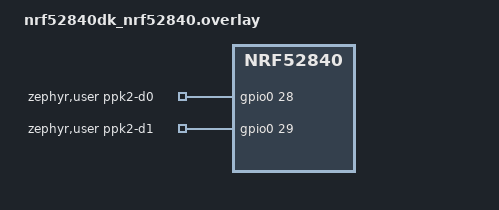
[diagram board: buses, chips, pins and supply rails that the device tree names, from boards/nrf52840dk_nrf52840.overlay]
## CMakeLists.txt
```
cmake_minimum_required(VERSION 3.20.0)
find_package(Zephyr REQUIRED HINTS $ENV{ZEPHYR_BASE})
project(zephyr_trace_demo LANGUAGES C CXX)

target_sources(app PRIVATE src/main.cpp)
target_include_directories(app PRIVATE include)
```

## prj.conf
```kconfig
# PPK2 trace-marker demo — minimal Zephyr config.
#
# GPIO for the two trace markers + the LED; C++17 for the RAII scope
# guard. Console/serial/logging are off so nothing but the workload
# shapes the current trace.

CONFIG_GPIO=y
CONFIG_CPP=y
CONFIG_STD_CPP17=y

CONFIG_LOG=n
CONFIG_PRINTK=n
CONFIG_BOOT_BANNER=n
CONFIG_CONSOLE=n
CONFIG_SERIAL=n
CONFIG_UART_CONSOLE=n
```

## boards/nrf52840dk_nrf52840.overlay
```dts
/*
 * nRF52840 DK (PCA10056) PPK2 trace pins: P0.28 (A2) -> D0,
 * P0.29 (A3) -> D1. Same pair as firmware/bench-dut (Arduino R3
 * analog header; unclaimed by default-enabled peripherals).
 */
/ {
	zephyr,user {
		ppk2-d0-gpios = <&gpio0 28 GPIO_ACTIVE_HIGH>;
		ppk2-d1-gpios = <&gpio0 29 GPIO_ACTIVE_HIGH>;
	};
};
```

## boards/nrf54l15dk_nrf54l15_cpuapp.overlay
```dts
/*
 * nRF54L15DK (PCA10156) PPK2 trace pins: P1.11 -> D0, P1.12 -> D1.
 * Same pair as firmware/bench-dut (routed to the GPIO connectors;
 * unclaimed by any default-enabled peripheral).
 */
/ {
	zephyr,user {
		ppk2-d0-gpios = <&gpio1 11 GPIO_ACTIVE_HIGH>;
		ppk2-d1-gpios = <&gpio1 12 GPIO_ACTIVE_HIGH>;
	};
};
```

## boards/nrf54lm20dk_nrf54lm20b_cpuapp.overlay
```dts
/*
 * nRF54LM20DK PPK2 trace pins: P1.12 -> D0, P1.13 -> D1.
 * Same pair as firmware/bench-dut (free of LED/button/UART duties;
 * on the GPIO_P1 header, so the PPK2 logic clips go straight on).
 */
/ {
	zephyr,user {
		ppk2-d0-gpios = <&gpio1 12 GPIO_ACTIVE_HIGH>;
		ppk2-d1-gpios = <&gpio1 13 GPIO_ACTIVE_HIGH>;
	};
};
```

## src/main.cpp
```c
/*
 * PPK2 trace-marker demo — a blinky whose energy you can attribute.
 *
 * Signal shape, repeating forever:
 *
 *   boot:  3 quick D0 pulses (C API)         — sync burst, marks reset
 *   sweep: D1 high for the whole sweep (RAII)
 *            10 × [ D0 high: 600 ms busy-blink workload (RAII)
 *                   D0 low:  150 ms idle gap (k_sleep)        ]
 *   rest:  2 s idle, then the sweep repeats
 *
 * D0 marks each workload, D1 each sweep. Capture with `ppk2 capture`
 * (or the Nordic GUI) and feed the CSV to attribute.py to get
 * per-workload and per-sweep energy.
 *
 * The workload is a busy-wait LED blink: the CPU stays awake, so the
 * current plateau during D0-high is visibly above the k_sleep gaps.
 */
#include <zephyr/drivers/gpio.h>
#include <zephyr/kernel.h>

#include "ppk2_trace.h"
#include "ppk2_trace.hpp"

#define N_RUNS       10
#define WORKLOAD_MS  600
#define BLINK_MS     100 /* LED toggle interval inside a workload */
#define GAP_MS       150 /* idle gap between workloads */
#define REST_MS      2000 /* idle rest between sweeps */

static const struct gpio_dt_spec led = GPIO_DT_SPEC_GET(DT_ALIAS(led0), gpios);

static void busy_blink_workload(void)
{
	for (int s = 0; s < WORKLOAD_MS / BLINK_MS; s++) {
		gpio_pin_toggle_dt(&led);
		k_busy_wait(BLINK_MS * 1000);
	}
}

/* C-API usage: a recognisable 3-pulse burst right after reset, handy
 * for locating t=0 in a capture that didn't start at power-on. */
static void sync_burst(void)
{
	for (int i = 0; i < 3; i++) {
		ppk2_trace_set(0, true);
		k_busy_wait(1000);
		ppk2_trace_set(0, false);
		k_busy_wait(1000);
	}
}

int main(void)
{
	if (ppk2_trace_init() != 0 || !gpio_is_ready_dt(&led) ||
	    gpio_pin_configure_dt(&led, GPIO_OUTPUT_INACTIVE) != 0) {
		return -1;
	}

	sync_burst();

	for (;;) {
		/* C++ RAII usage: D1 brackets the sweep, D0 each workload. */
		ppk2::trace_scope(ppk2::D1, [] {
			for (int i = 0; i < N_RUNS; i++) {
				ppk2::trace_scope(ppk2::D0, [] { busy_blink_workload(); });
				k_sleep(K_MSEC(GAP_MS));
			}
		});
		k_sleep(K_MSEC(REST_MS));
	}
	return 0;
}
```

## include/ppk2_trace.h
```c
/*
 * PPK2 trace markers — C API.
 *
 * Two GPIO markers wired to the PPK2's D0/D1 logic inputs, declared
 * in the board overlay as `zephyr,user` properties:
 *
 *     / {
 *         zephyr,user {
 *             ppk2-d0-gpios = <&gpio1 12 GPIO_ACTIVE_HIGH>;
 *             ppk2-d1-gpios = <&gpio1 13 GPIO_ACTIVE_HIGH>;
 *         };
 *     };
 *
 * The PPK2 samples the logic pins with every current sample
 * (100 kSPS), so a marker held high during a code region lets the
 * host attribute energy to that region with 10 µs granularity.
 *
 * Header-only; include from C or C++. For C++ scope guards on top of
 * these markers, see ppk2_trace.hpp.
 */
#ifndef PPK2_TRACE_H
#define PPK2_TRACE_H

#include <stdbool.h>

#include <zephyr/drivers/gpio.h>

#ifdef __cplusplus
extern "C" {
#endif

#define PPK2_TRACE_NODE DT_PATH(zephyr_user)
BUILD_ASSERT(DT_NODE_HAS_PROP(PPK2_TRACE_NODE, ppk2_d0_gpios),
	     "board overlay must define zephyr,user ppk2-d0-gpios");
BUILD_ASSERT(DT_NODE_HAS_PROP(PPK2_TRACE_NODE, ppk2_d1_gpios),
	     "board overlay must define zephyr,user ppk2-d1-gpios");

static const struct gpio_dt_spec ppk2_trace_pins[2] = {
	GPIO_DT_SPEC_GET(PPK2_TRACE_NODE, ppk2_d0_gpios),
	GPIO_DT_SPEC_GET(PPK2_TRACE_NODE, ppk2_d1_gpios),
};

/* Configure both marker pins as outputs, driven low. 0 on success. */
static inline int ppk2_trace_init(void)
{
	for (int i = 0; i < 2; i++) {
		if (!gpio_is_ready_dt(&ppk2_trace_pins[i])) {
			return -1;
		}
		int err = gpio_pin_configure_dt(&ppk2_trace_pins[i], GPIO_OUTPUT_INACTIVE);
		if (err) {
			return err;
		}
	}
	return 0;
}

/* Drive marker `ch` (0 = PPK2 D0, 1 = PPK2 D1) high or low. */
static inline void ppk2_trace_set(int ch, bool on)
{
	(void)gpio_pin_set_dt(&ppk2_trace_pins[ch & 1], on ? 1 : 0);
}

#ifdef __cplusplus
}
#endif

#endif /* PPK2_TRACE_H */
```

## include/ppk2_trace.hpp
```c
/*
 * PPK2 trace markers — C++ RAII layer on top of ppk2_trace.h.
 *
 * A TraceScope raises a marker on construction and lowers it on
 * destruction, so the marked region survives early returns and
 * exceptions-disabled error paths alike:
 *
 *     {
 *         ppk2::TraceScope mark{ppk2::D0};
 *         run_inference();
 *     }   // D0 drops here, whatever run_inference did
 *
 * trace_scope() is the lambda-shaped convenience for one-liners:
 *
 *     ppk2::trace_scope(ppk2::D1, [&] { whole_sweep(); });
 */
#ifndef PPK2_TRACE_HPP
#define PPK2_TRACE_HPP

#include "ppk2_trace.h"

namespace ppk2 {

inline constexpr int D0 = 0;
inline constexpr int D1 = 1;

class TraceScope {
public:
	explicit TraceScope(int ch) : m_ch(ch) { ppk2_trace_set(m_ch, true); }
	~TraceScope() { ppk2_trace_set(m_ch, false); }

	TraceScope(const TraceScope &) = delete;
	TraceScope &operator=(const TraceScope &) = delete;

private:
	int m_ch;
};

/* Run `body` with marker `ch` held high; lowered on scope exit. */
template <typename Body>
inline void trace_scope(int ch, Body &&body)
{
	TraceScope guard{ch};
	body();
}

} /* namespace ppk2 */

#endif /* PPK2_TRACE_HPP */
```
